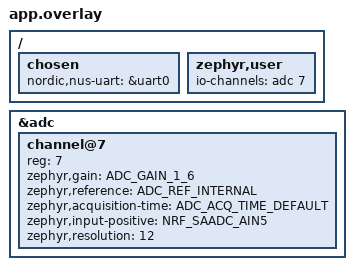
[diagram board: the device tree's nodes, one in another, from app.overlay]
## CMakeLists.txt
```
#
# Copyright (c) 2018 Nordic Semiconductor
#
# SPDX-License-Identifier: LicenseRef-Nordic-5-Clause
#
cmake_minimum_required(VERSION 3.20.0)

find_package(Zephyr REQUIRED HINTS $ENV{ZEPHYR_BASE})
project(homeflow_embedded_final)

# NORDIC SDK APP START
target_sources(app PRIVATE
  src/main.c
  src/bme.c
  src/temp.c
  src/r_enc.c
  src/imu.c
  src/rc_filter.c
  src/hr.c
  src/display.c
  src/ring_buf.c
  src/spi.c
  src/mutexes.c
)

# Include UART ASYNC API adapter
target_sources_ifdef(CONFIG_BT_NUS_UART_ASYNC_ADAPTER app PRIVATE
  src/uart_async_adapter.c
)

# NORDIC SDK APP END

zephyr_library_include_directories(.)
```

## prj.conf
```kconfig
#
# Copyright (c) 2018 Nordic Semiconductor
#
# SPDX-License-Identifier: LicenseRef-Nordic-5-Clause
#

# Enable the UART driver
CONFIG_UART_ASYNC_API=y
CONFIG_NRFX_UARTE0=y
CONFIG_SERIAL=y
CONFIG_POSIX_API=y
CONFIG_NEWLIB_LIBC=y


#enable I2C
CONFIG_I2C=y
CONFIG_I2C_NRFX=y

CONFIG_GPIO=y

# Make sure printk is printing to the UART console
CONFIG_CONSOLE=y
CONFIG_UART_CONSOLE=y

CONFIG_HEAP_MEM_POOL_SIZE=2048

CONFIG_BT=y
CONFIG_BT_PERIPHERAL=y
CONFIG_BT_DEVICE_NAME="HomeFlow"
CONFIG_BT_DEVICE_APPEARANCE=833
CONFIG_BT_MAX_CONN=1
CONFIG_BT_MAX_PAIRED=1

# Enable the NUS service
CONFIG_BT_NUS=y

# Enable bonding
CONFIG_BT_SETTINGS=y
CONFIG_FLASH=y
CONFIG_FLASH_PAGE_LAYOUT=y
CONFIG_FLASH_MAP=y
CONFIG_NVS=y
CONFIG_SETTINGS=y

# Enable DK LED and Buttons library
CONFIG_DK_LIBRARY=y

# This example requires more stack
CONFIG_MAIN_STACK_SIZE=2048
CONFIG_SYSTEM_WORKQUEUE_STACK_SIZE=2048

# Config logger
CONFIG_LOG=y
CONFIG_USE_SEGGER_RTT=y
CONFIG_LOG_BACKEND_RTT=y
CONFIG_LOG_BACKEND_UART=n
CONFIG_LOG_PRINTK=n

CONFIG_ASSERT=y

#enable float printing
CONFIG_STDOUT_CONSOLE=y
CONFIG_NEWLIB_LIBC=y
CONFIG_NEWLIB_LIBC_FLOAT_PRINTF=y

CONFIG_SPI=y
CONFIG_ADC=y
```

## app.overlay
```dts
/*
 * Copyright (c) 2022 Nordic Semiconductor ASA
 *
 * SPDX-License-Identifier: LicenseRef-Nordic-5-Clause
 */

/ {
	chosen {
		nordic,nus-uart = &uart0;
	};

	zephyr,user {
		io-channels = <&adc 7>;
	};
};

&adc {
	#address-cells = <1>;
	#size-cells = <0>;

	channel@7 {
		reg = <7>;
		zephyr,gain = "ADC_GAIN_1_6";
		zephyr,reference = "ADC_REF_INTERNAL";
		zephyr,acquisition-time = <ADC_ACQ_TIME_DEFAULT>;
		zephyr,input-positive = <NRF_SAADC_AIN5>; /* P0.29 */
		zephyr,resolution = <12>;
	};
};
```

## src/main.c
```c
#include <zephyr/types.h>
#include <zephyr/zephyr.h>
#include <stddef.h>
#include <string.h>
#include <errno.h>
#include <zephyr/sys/printk.h>
#include <zephyr/sys/byteorder.h>
#include <zephyr/kernel.h>

#include "bluetooth.c"
#include "../inc/spi.h"
#include "../inc/r_enc.h"
#include "../inc/bme.h"
#include "../inc/temp.h"
#include "../inc/hr.h"
#include "../inc/imu.h"
#include "../inc/display.h"
#include "../inc/mutexes.h"

#include <zephyr/device.h>
#include <zephyr/drivers/i2c.h>
#include <zephyr/devicetree.h>

#include <inttypes.h>
#include <stddef.h>
#include <stdint.h>
#include <stdio.h>

#include <zephyr/device.h>
#include <zephyr/devicetree.h>
#include <zephyr/drivers/adc.h>
#include <zephyr/kernel.h>
#include <zephyr/sys/printk.h>
#include <zephyr/sys/util.h>
#include <hal/nrf_saadc.h>

const struct device* i2c0_dev = DEVICE_DT_GET(DT_NODELABEL(i2c0));
const struct device* gpio1_dev = DEVICE_DT_GET(DT_NODELABEL(gpio1));
const struct device* gpio0_dev = DEVICE_DT_GET(DT_NODELABEL(gpio0));
const struct device* spi1_dev = DEVICE_DT_GET(DT_NODELABEL(spi1));

#define IMU_STACK_SIZE 2048
#define IMU_PRIORITY 8
K_THREAD_STACK_DEFINE(imu_thread_stack, IMU_STACK_SIZE);
struct k_thread imu_thread_data;

#define DISPLAY_STACK_SIZE 1024
#define DISPLAY_PRIORITY 1
K_THREAD_STACK_DEFINE(display_thread_stack, DISPLAY_STACK_SIZE);
struct k_thread display_thread_data;


int main(void)
{
	//ble init
	initialize_ble();

	BME688_Init();

	// IMU init
	init_IMU_cs();
	init_IMU();
	init_RCFilters();

	//r_enc init
	init_enc();

	// Heart rate sensor initialization
	init_hr();

	//mutex init for shared resources
	init_mutexes();
	
	sensor_data data;
	int steps = 0;

	k_thread_create(&imu_thread_data, imu_thread_stack, K_THREAD_STACK_SIZEOF(imu_thread_stack),
					imu_thread_entry, &steps, NULL, NULL, IMU_PRIORITY, 0, K_NO_WAIT);
	k_thread_create(&display_thread_data, display_thread_stack, K_THREAD_STACK_SIZEOF(display_thread_stack),
					display_thread_entry, &data, &steps, NULL, DISPLAY_PRIORITY, 0, K_NO_WAIT);
	k_thread_start(&imu_thread_data);
	k_thread_start(&display_thread_data);

	while (1) {
		k_msleep(1000);

		char temp_buf[10];
		char humidity_buf[10];
		char temp_c_buf[10];
		char gas_buf[10];
		char pressure_buf[10];
		char hr_buf[10];
		char spo2_buf[10];
		char hr_confidence_buf[10];
		char step_buf[10];
		char xl_x_buf[10];
		char xl_y_buf[10];
		char xl_z_buf[10];

		//poll I2C sensors
		k_mutex_lock(&i2c_lock, K_FOREVER);

		//body temp sensor
		data.body_temp = get_body_temp();
		snprintf(temp_buf, sizeof(temp_buf), "BTS:%f", data.body_temp);

		//weather sensor
		BME688_Take_Measurement();
		data.humidity = (float)BME688_Get_Humidity();
		snprintf(humidity_buf, sizeof(humidity_buf), "BMH:%f", data.humidity);
		data.weather_temp = (float)BME688_Get_Temp_C();
		snprintf(temp_c_buf, sizeof(temp_c_buf), "BMT:%f", (data.weather_temp*1.8)+32);
		data.aqi = (float)BME688_Get_Gas();
		snprintf(gas_buf, sizeof(gas_buf), "BMG:%f", data.aqi);
		data.pressure = (float)BME688_Get_Pressure();
		snprintf(pressure_buf, sizeof(pressure_buf), "BMP:%f", data.pressure);

		//hr sensor
		float* hr_data = read_hr();
		data.hr = hr_data[0];
		data.hr_confidence = (int)hr_data[1];
		data.bos = hr_data[2];
		snprintf(hr_buf, sizeof(hr_buf), "BPM:%f", data.hr);
		snprintf(spo2_buf, sizeof(spo2_buf), "BOS:%f", data.bos);
		snprintf(hr_confidence_buf, sizeof(hr_confidence_buf), "HRC:%d", data.hr_confidence);

		k_mutex_unlock(&i2c_lock);

		//read step count
		k_mutex_lock(&steps_lock, K_FOREVER);
		snprintf(step_buf, sizeof(step_buf), "STP:%d", steps);
		k_mutex_unlock(&steps_lock);

		//read IMU readings
		k_mutex_lock(&imu_lock, K_FOREVER);
		snprintf(xl_x_buf, sizeof(xl_x_buf), "XLX:%f", IMU_readings[0]);
		snprintf(xl_y_buf, sizeof(xl_y_buf), "XLY:%f", IMU_readings[1]);
		snprintf(xl_z_buf, sizeof(xl_z_buf), "XLZ:%f", IMU_readings[2]);
		k_mutex_unlock(&imu_lock);

		if (current_conn) {
			bt_nus_send(current_conn, temp_buf, strlen(temp_buf));
			bt_nus_send(current_conn, humidity_buf, strlen(humidity_buf));
			bt_nus_send(current_conn, temp_c_buf, strlen(temp_c_buf));
			bt_nus_send(current_conn, gas_buf, strlen(gas_buf));
			bt_nus_send(current_conn, pressure_buf, strlen(pressure_buf));
			bt_nus_send(current_conn, step_buf, strlen(step_buf));
			bt_nus_send(current_conn, hr_buf, strlen(hr_buf));
			bt_nus_send(current_conn, spo2_buf, strlen(spo2_buf));
			bt_nus_send(current_conn, hr_confidence_buf, strlen(hr_confidence_buf));
			bt_nus_send(current_conn, xl_x_buf, strlen(xl_x_buf));
			bt_nus_send(current_conn, xl_y_buf, strlen(xl_y_buf));
			bt_nus_send(current_conn, xl_z_buf, strlen(xl_z_buf));
		}
	}
	return 0;
}
```

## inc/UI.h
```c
#include "r_enc.h"
#include "display.h"
```

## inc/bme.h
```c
#ifndef BME
#define BME
#include <stdint.h>
#include <zephyr/drivers/i2c.h>

extern const struct device* i2c0_dev;

void BME688_Init();
void BME688_Take_Measurement();
double BME688_Get_Temp_C();
double BME688_Get_Humidity();
double BME688_Get_Pressure();
double BME688_Get_Gas();
#endif
```

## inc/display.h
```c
#ifndef DISPLAY_H
#define DISPLAY_H

#include <zephyr/types.h>
#include <zephyr/drivers/gpio.h>
#include <zephyr/drivers/spi.h>
#include <zephyr/logging/log.h>
#include <stdbool.h>
#include "mutexes.h"

#define P0_03 3
#define P0_04 4

extern int display_var;
extern const struct device* spi1_dev;
extern const struct device* gpio0_dev;
extern volatile bool cw_detected;
extern volatile bool ccw_detected;

typedef struct {
    float hr;
    int hr_confidence;
    float bos;
    float body_temp;
    int steps;
    float weather_temp;
    float humidity;
    float aqi;
    float pressure;
} sensor_data;

typedef enum {
    HEART_RATE_SCREEN,
    BLOOD_OXYGEN_SCREEN,
    BODY_TEMP_SCREEN,
    ACTIVITY_SCREEN,
    WEATHER_SCREEN,
    WARNING_SCREEN,
    NUM_SCREENS // This should always be the last element
} DisplayState;

// Function to initialize the display
void main_display_init(const struct device *spi1_dev, const struct device *gpio0_dev, uint16_t backgroundColor, uint16_t heartColor);

// Function to update the display (could be used for periodic updates or refreshes)
uint16_t main_display_update_test(const struct device *spi1_dev, const struct device *gpio0_dev, uint16_t color);

// Set the row address
void st7789v_set_row_address(const struct device *spi_dev, const struct device *gpio_dev, uint16_t start, uint16_t end);

// Set the column address
void st7789v_set_column_address(const struct device *spi_dev, const struct device *gpio_dev, uint16_t start, uint16_t end);

// Resets and prepares the display hardware
void reset_display(const struct device *reset_gpio);

// Sends commands to the display
void st7789v_send_command(const struct device *spi_dev, const struct device *gpio_dev, uint8_t command);

// Sends data to the display
void st7789v_send_data(const struct device *spi_dev, const struct device *gpio_dev, uint8_t *data, size_t len);

// Initializes the ST7789V display controller
void st7789v_init_display(const struct device *spi_dev, const struct device *gpio_dev);

// Draws a filled rectangle on the display
void st7789v_fill_rect(const struct device *spi_dev, const struct device *gpio_dev, uint16_t x, uint16_t y, uint16_t width, uint16_t height, uint16_t color);

// Optimized function to fill a rectangle with a single color
void st7789v_fill_rect_optimized(const struct device *spi_dev, const struct device *gpio_dev, uint16_t x, uint16_t y, uint16_t width, uint16_t height, uint16_t color);

void draw_thicker_heart(const struct device *spi_dev, const struct device *gpio_dev, int centerX, int centerY, int size, uint16_t color, int thickness);

void display_thread_entry(void *p1, void *p2, void *p3);

#endif // DISPLAY_H
```

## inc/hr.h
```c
#ifndef HR
#define HR
#include <stdint.h>
#include <zephyr/drivers/gpio.h>
#include <zephyr/kernel.h>
#include <zephyr/drivers/i2c.h>

#define MFIO 11 //PIN_0_11
#define RST 12 //PIN_0_12

extern uint8_t HR_ADDR;

extern const struct device* gpio0_dev;
extern const struct device* i2c0_dev;

void init_hr();
float* read_hr();

#endif
```

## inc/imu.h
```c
/*
SPI1 pins:
VIN:  vdd
INT1: P102
SCL: PO31
SDA: PO30
CSAG: P107
SDOAG: P108

SPI3 pins:
VIN:  vdd
INT1 (white): P102
CSAG (brown): P107
SCL/SCK (blue): P115
SDA/MOSI (gray): P113
SDOAG/MISO (orange): P114
*/

#ifndef IMU_H
#define IMU_H

#include <zephyr/kernel.h>
#include <zephyr/drivers/gpio.h>
#include <zephyr/drivers/spi.h>
#include <stdlib.h>
#include <stdio.h>
#include <string.h>
#include <zephyr/sys/printk.h>
#include <zephyr/device.h>
#include <zephyr/logging/log.h>
#include <math.h>
#include <zephyr/sys/ring_buffer.h>
#include <stdbool.h>

#include "rc_filter.h"
#include "ring_buf.h"
#include "mutexes.h"

//relevant registers masks used for IMU
#define CHIPID_REG_READ 0b10001111
#define CTRL_REG1_G_WRITE 0b00010000
#define CTRL_REG1_G_READ 0b10010000
#define ACCEL_X_UPPER 0b10101001
#define ACCEL_X_LOWER 0b10101000
#define ACCEL_Y_UPPER 0b10101011
#define ACCEL_Y_LOWER 0b10101010
#define ACCEL_Z_UPPER 0b10101101
#define ACCEL_Z_LOWER 0b10101100
#define G_X_UPPER 0b10011001
#define G_X_LOWER 0b10011000
#define G_Y_UPPER 0b10011011
#define G_Y_LOWER 0b10011010
#define G_Z_UPPER 0b10011101
#define G_Z_LOWER 0b10011100
#define CTRL_REG1_G_952_ODR 0b11000000
#define INT1_CTRL_READ 0b10001100
#define INT1_CTRL_WRITE 0b00001100
#define INT_IG_XL 0b01000000
#define INT_GEN_CFG_XL_READ 0b10000110
#define INT_GEN_CFG_XL_WRITE 0b00000110
#define XHIE_XL 0b00000010
#define XLIE_XL 0b00000001
#define INT_GEN_THS_X_XL_WRITE 0b00000111
#define INT_GEN_THS_X_XL_READ 0b10000111
#define STATUS_REG_READ 0b10010111
#define INT_GEN_SRC_XL_READ 0b10100110
#define INT_GEN_SRC_XL_WRITE 0b00100110
#define STATUS_REG_READ 0b10010111
#define STATUS_REG_WRITE 0b00010111
#define CTRL_REG6_XL_READ 0b10100000
#define CTRL_REG6_XL_WRITE 0b00100000
#define CTRL_REG6_XL_FS_XL_8G 0b00011000
#define CTRL_REG6_XL_ODR_XL_952 0b11000000
#define FS_XL_4G 0b00010000

#define PIN_1_02 2
#define SPI3_NODE DT_NODELABEL (spi3)
#define MY_GPI01 DT_NODELABEL (gpio1)
#define GPIO_1_CS 7

#define NUM_AXES 6
#define XL_X_IND 0
#define XL_Y_IND 1
#define XL_Z_IND 2
#define G_X_IND 3
#define G_Y_IND 4
#define G_Z_IND 5

#define SAMPLING_INTERVAL_MS 10  // Sampling rate = 1 / SAMPLING_INTERVAL_S
#define ALPHA 0.1

#define A0 0.020083365564211235
#define A1 0.04016673112842247
#define A2 0.020083365564211235
#define B1 -1.5610180758007182
#define B2 0.6413515380575631

// Butterworth filter state
typedef struct {
    float x[2];  // Input samples
    float y[2];  // Output samples
} ButterworthFilter;

extern const struct device *spi3_dev;
extern struct spi_config spi3_cfg;
extern const struct device* gpio0_dev;
extern const struct device *gpio1_dev;
// extern struct gpio_callback gpio_cb;

//order of indices: xl_x, xl_y, xl_z, g_x, g_y, g_z
extern RCFilter lp_filters[NUM_AXES]; 
extern float cutoff_freqs[NUM_AXES];

extern volatile float IMU_readings[NUM_AXES]; //sensor readings in g's and dps
extern volatile int interrupt_called;
extern volatile int max_x;
extern volatile float filtered_imu_data[3];
extern volatile float threshold;

void spi_read_reg(uint8_t reg, uint8_t values[], uint8_t size);
void spi_write_reg(uint8_t reg, uint8_t data, uint8_t size);
void init_IMU();
void init_IMU_interrupts();
void IMU_interrupt_cb(const struct device *dev, struct gpio_callback *cb, uint32_t pins);
void init_IMU_cs();
float poll_IMU(); //returns magnitude of IMU readings
void init_RCFilters();
void imu_thread_entry(void *p1, void *p2, void *p3);
float calc_magnitude(float x, float y, float z);
float ema_filter(float new_mag, float old_mag);
void init_butterworth_filter(ButterworthFilter* filter);
float butterworth_filter(ButterworthFilter* filter, float input);
bool detect_step(float magnitude, ring_buf* samps, ring_buf* intervals, long* last_step_time_ms);

#endif
```

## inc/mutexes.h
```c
#pragma once

#include <zephyr/kernel.h>

extern void init_mutexes();

extern struct k_mutex steps_lock; //for steps
extern struct k_mutex i2c_lock; //for sensor_data struct in main
extern struct k_mutex imu_lock; //for IMU_readings[]
```

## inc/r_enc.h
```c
#ifndef R_ENC_H
#define R_ENC_H

#include <zephyr/kernel.h>
#include <zephyr/drivers/gpio.h>
#include <stdlib.h>
#include <stdio.h>
#include <string.h>
#include <zephyr/sys/printk.h>
#include <zephyr/logging/log.h>
#include <stdbool.h>

// Assign pins A, B, and BTN to P104, P105, & P106 respectively
#define P0_03 3
#define P0_04 4
#define P1_08 8 // NOTE: P0_05 didn't work for some reason (the intended pin), might be due to HW issues on DK board
#define PIN_A 24
#define PIN_B 25
#define PIN_C 0
#define PIN_LED 13

extern const struct device *gpio0_dev;
extern const struct device *gpio1_dev;
extern volatile bool cw_detected;
extern volatile bool ccw_detected;

//initialize gpios for encoder
void init_enc();
void set_decoder_state(const struct device *dev, uint8_t state);
void process_encoder_input(const struct device *dev, uint8_t pin_a_val, uint8_t pin_b_val);
void encoder_isr(const struct device *dev, struct gpio_callback *cb, uint32_t pins);
void click_isr(const struct device *dev, struct gpio_callback *cb, uint32_t pins);
void debounce_twist(const struct device *dev, uint8_t enc_val);
void debounce_button(const struct device *dev);
void check_enc_btn();

#endif
```

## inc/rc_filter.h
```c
#ifndef RC_FILTER_H
#define RC_FILTER_H

//SW RC circuit filter
typedef struct {
	float coeff[2];
	float out[2];

} RCFilter;

void RCFilter_Init(RCFilter *filt, float cutoffFreqHz, float sampleTimeS);
float RCFilter_Update(RCFilter *filt, float inp);

#endif
```

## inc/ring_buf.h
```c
#define BUF_SIZE 10

typedef struct {
    float buffer[BUF_SIZE];
    int curr_index;
} ring_buf;

void insert_val(float accel, ring_buf* b);
float get_rolling_avg(ring_buf* b);
```

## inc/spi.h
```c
#ifndef SPI_H
#define SPI_H

#include <zephyr/types.h>
#include <zephyr/drivers/spi.h>

extern struct spi_config spi_cfg; // Declare the external SPI configuration to be used by other files.

int spi_write1(const struct device *spi_dev, uint8_t *data, size_t data_len, struct spi_config sg);

#endif // SPI_H
```

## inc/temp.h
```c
#include <stdint.h>
#include <zephyr/drivers/i2c.h>
extern const struct device* i2c0_dev;

float get_body_temp();
```

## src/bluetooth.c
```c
/*
 * Copyright (c) 2018 Nordic Semiconductor ASA
 *
 * SPDX-License-Identifier: LicenseRef-Nordic-5-Clause
 */

/** @file
 *  @brief Nordic UART Bridge Service (NUS) sample
 */
#include "../inc/uart_async_adapter.h"

#include <zephyr/types.h>
#include <zephyr/kernel.h>
#include <zephyr/drivers/uart.h>
#include <zephyr/usb/usb_device.h>

#include <zephyr/device.h>
#include <zephyr/devicetree.h>
#include <soc.h>

#include <zephyr/bluetooth/bluetooth.h>
#include <zephyr/bluetooth/uuid.h>
#include <zephyr/bluetooth/gatt.h>
#include <zephyr/bluetooth/hci.h>

#include <bluetooth/services/nus.h>

#include <dk_buttons_and_leds.h>

#include <zephyr/settings/settings.h>

#include <stdio.h>

#include <zephyr/logging/log.h>

#include "../inc/bluetooth.h"

#define LOG_MODULE_NAME peripheral_uart
LOG_MODULE_REGISTER(LOG_MODULE_NAME);

#define STACKSIZE 1024
#define PRIORITY 7

#define DEVICE_NAME CONFIG_BT_DEVICE_NAME
#define DEVICE_NAME_LEN	(sizeof(DEVICE_NAME) - 1)

#define RUN_STATUS_LED DK_LED1
#define RUN_LED_BLINK_INTERVAL 1000

#define CON_STATUS_LED DK_LED2

#define KEY_PASSKEY_ACCEPT DK_BTN1_MSK
#define KEY_PASSKEY_REJECT DK_BTN2_MSK

#define UART_BUF_SIZE CONFIG_BT_NUS_UART_BUFFER_SIZE
#define UART_WAIT_FOR_BUF_DELAY K_MSEC(50)
#define UART_WAIT_FOR_RX CONFIG_BT_NUS_UART_RX_WAIT_TIME

K_SEM_DEFINE(ble_init_ok, 0, 1);

static struct bt_conn *current_conn;
static struct bt_conn *auth_conn;

static const struct device *uart = DEVICE_DT_GET(DT_CHOSEN(nordic_nus_uart));
static struct k_work_delayable uart_work;

struct uart_data_t {
	void *fifo_reserved;
	uint8_t data[UART_BUF_SIZE];
	uint16_t len;
};

static K_FIFO_DEFINE(fifo_uart_tx_data);
static K_FIFO_DEFINE(fifo_uart_rx_data);

const struct bt_data ad[] = {
	BT_DATA_BYTES(BT_DATA_FLAGS, (BT_LE_AD_GENERAL | BT_LE_AD_NO_BREDR)),
	BT_DATA(BT_DATA_NAME_COMPLETE, DEVICE_NAME, DEVICE_NAME_LEN),
};

const struct bt_data sd[] = {
	BT_DATA_BYTES(BT_DATA_UUID128_ALL, BT_UUID_NUS_VAL),
};

#if CONFIG_BT_NUS_UART_ASYNC_ADAPTER
UART_ASYNC_ADAPTER_INST_DEFINE(async_adapter);
#else
static const struct device *const async_adapter;
#endif

static void uart_cb(const struct device *dev, struct uart_event *evt, void *user_data)
{
	ARG_UNUSED(dev);

	static size_t aborted_len;
	struct uart_data_t *buf;
	static uint8_t *aborted_buf;
	static bool disable_req;

	switch (evt->type) {
	case UART_TX_DONE:
		LOG_DBG("UART_TX_DONE");
		if ((evt->data.tx.len == 0) ||
		    (!evt->data.tx.buf)) {
			return;
		}

		if (aborted_buf) {
			buf = CONTAINER_OF(aborted_buf, struct uart_data_t,
					   data);
			aborted_buf = NULL;
			aborted_len = 0;
		} else {
			buf = CONTAINER_OF(evt->data.tx.buf, struct uart_data_t,
					   data);
		}

		k_free(buf);

		buf = k_fifo_get(&fifo_uart_tx_data, K_NO_WAIT);
		if (!buf) {
			return;
		}

		if (uart_tx(uart, buf->data, buf->len, SYS_FOREVER_MS)) {
			LOG_WRN("Failed to send data over UART");
		}

		break;

	case UART_RX_RDY:
		LOG_DBG("UART_RX_RDY");
		buf = CONTAINER_OF(evt->data.rx.buf, struct uart_data_t, data);
		buf->len += evt->data.rx.len;

		if (disable_req) {
			return;
		}

		if ((evt->data.rx.buf[buf->len - 1] == '\n') ||
		    (evt->data.rx.buf[buf->len - 1] == '\r')) {
			disable_req = true;
			uart_rx_disable(uart);
		}

		break;

	case UART_RX_DISABLED:
		LOG_DBG("UART_RX_DISABLED");
		disable_req = false;

		buf = k_malloc(sizeof(*buf));
		if (buf) {
			buf->len = 0;
		} else {
			LOG_WRN("Not able to allocate UART receive buffer");
			k_work_reschedule(&uart_work, UART_WAIT_FOR_BUF_DELAY);
			return;
		}

		uart_rx_enable(uart, buf->data, sizeof(buf->data),
			       UART_WAIT_FOR_RX);

		break;

	case UART_RX_BUF_REQUEST:
		LOG_DBG("UART_RX_BUF_REQUEST");
		buf = k_malloc(sizeof(*buf));
		if (buf) {
			buf->len = 0;
			uart_rx_buf_rsp(uart, buf->data, sizeof(buf->data));
		} else {
			LOG_WRN("Not able to allocate UART receive buffer");
		}

		break;

	case UART_RX_BUF_RELEASED:
		LOG_DBG("UART_RX_BUF_RELEASED");
		buf = CONTAINER_OF(evt->data.rx_buf.buf, struct uart_data_t,
				   data);

		if (buf->len > 0) {
			k_fifo_put(&fifo_uart_rx_data, buf);
		} else {
			k_free(buf);
		}

		break;

	case UART_TX_ABORTED:
		LOG_DBG("UART_TX_ABORTED");
		if (!aborted_buf) {
			aborted_buf = (uint8_t *)evt->data.tx.buf;
		}

		aborted_len += evt->data.tx.len;
		buf = CONTAINER_OF(aborted_buf, struct uart_data_t,
				   data);

		uart_tx(uart, &buf->data[aborted_len],
			buf->len - aborted_len, SYS_FOREVER_MS);

		break;

	default:
		break;
	}
}

static void uart_work_handler(struct k_work *item)
{
	struct uart_data_t *buf;

	buf = k_malloc(sizeof(*buf));
	if (buf) {
		buf->len = 0;
	} else {
		LOG_WRN("Not able to allocate UART receive buffer");
		k_work_reschedule(&uart_work, UART_WAIT_FOR_BUF_DELAY);
		return;
	}

	uart_rx_enable(uart, buf->data, sizeof(buf->data), UART_WAIT_FOR_RX);
}

static bool uart_test_async_api(const struct device *dev)
{
	const struct uart_driver_api *api =
			(const struct uart_driver_api *)dev->api;

	return (api->callback_set != NULL);
}

static int uart_init(void)
{
	int err;
	int pos;
	struct uart_data_t *rx;
	struct uart_data_t *tx;

	if (!device_is_ready(uart)) {
		return -ENODEV;
	}

	if (IS_ENABLED(CONFIG_USB_DEVICE_STACK)) {
		err = usb_enable(NULL);
		if (err && (err != -EALREADY)) {
			LOG_ERR("Failed to enable USB");
			return err;
		}
	}

	rx = k_malloc(sizeof(*rx));
	if (rx) {
		rx->len = 0;
	} else {
		return -ENOMEM;
	}

	k_work_init_delayable(&uart_work, uart_work_handler);


	if (IS_ENABLED(CONFIG_BT_NUS_UART_ASYNC_ADAPTER) && !uart_test_async_api(uart)) {
		/* Implement API adapter */
		uart_async_adapter_init(async_adapter, uart);
		uart = async_adapter;
	}

	err = uart_callback_set(uart, uart_cb, NULL);
	if (err) {
		k_free(rx);
		LOG_ERR("Cannot initialize UART callback");
		return err;
	}

	if (IS_ENABLED(CONFIG_UART_LINE_CTRL)) {
		LOG_INF("Wait for DTR");
		while (true) {
			uint32_t dtr = 0;

			uart_line_ctrl_get(uart, UART_LINE_CTRL_DTR, &dtr);
			if (dtr) {
				break;
			}
			/* Give CPU resources to low priority threads. */
			k_sleep(K_MSEC(100));
		}
		LOG_INF("DTR set");
		err = uart_line_ctrl_set(uart, UART_LINE_CTRL_DCD, 1);
		if (err) {
			LOG_WRN("Failed to set DCD, ret code %d", err);
		}
		err = uart_line_ctrl_set(uart, UART_LINE_CTRL_DSR, 1);
		if (err) {
			LOG_WRN("Failed to set DSR, ret code %d", err);
		}
	}

	tx = k_malloc(sizeof(*tx));

	if (tx) {
		pos = snprintf(tx->data, sizeof(tx->data),
			       "Starting Nordic UART service example\r\n");

		if ((pos < 0) || (pos >= sizeof(tx->data))) {
			k_free(rx);
			k_free(tx);
			LOG_ERR("snprintf returned %d", pos);
			return -ENOMEM;
		}

		tx->len = pos;
	} else {
		k_free(rx);
		return -ENOMEM;
	}

	err = uart_tx(uart, tx->data, tx->len, SYS_FOREVER_MS);
	if (err) {
		k_free(rx);
		k_free(tx);
		LOG_ERR("Cannot display welcome message (err: %d)", err);
		return err;
	}

	err = uart_rx_enable(uart, rx->data, sizeof(rx->data), 50);
	if (err) {
		LOG_ERR("Cannot enable uart reception (err: %d)", err);
		/* Free the rx buffer only because the tx buffer will be handled in the callback */
		k_free(rx);
	}

	return err;
}

static void connected(struct bt_conn *conn, uint8_t err)
{
	char addr[BT_ADDR_LE_STR_LEN];

	if (err) {
		LOG_ERR("Connection failed (err %u)", err);
		return;
	}

	bt_addr_le_to_str(bt_conn_get_dst(conn), addr, sizeof(addr));
	LOG_INF("Connected %s", addr);

	current_conn = bt_conn_ref(conn);

	dk_set_led_on(CON_STATUS_LED);
}

static void disconnected(struct bt_conn *conn, uint8_t reason)
{
	char addr[BT_ADDR_LE_STR_LEN];

	bt_addr_le_to_str(bt_conn_get_dst(conn), addr, sizeof(addr));

	LOG_INF("Disconnected: %s (reason %u)", addr, reason);

	if (auth_conn) {
		bt_conn_unref(auth_conn);
		auth_conn = NULL;
	}

	if (current_conn) {
		bt_conn_unref(current_conn);
		current_conn = NULL;
		dk_set_led_off(CON_STATUS_LED);
	}
}

#ifdef CONFIG_BT_NUS_SECURITY_ENABLED
static void security_changed(struct bt_conn *conn, bt_security_t level,
			     enum bt_security_err err)
{
	char addr[BT_ADDR_LE_STR_LEN];

	bt_addr_le_to_str(bt_conn_get_dst(conn), addr, sizeof(addr));

	if (!err) {
		LOG_INF("Security changed: %s level %u", addr, level);
	} else {
		LOG_WRN("Security failed: %s level %u err %d", addr,
			level, err);
	}
}
#endif

BT_CONN_CB_DEFINE(conn_callbacks) = {
	.connected    = connected,
	.disconnected = disconnected,
#ifdef CONFIG_BT_NUS_SECURITY_ENABLED
	.security_changed = security_changed,
#endif
};

#if defined(CONFIG_BT_NUS_SECURITY_ENABLED)
static void auth_passkey_display(struct bt_conn *conn, unsigned int passkey)
{
	char addr[BT_ADDR_LE_STR_LEN];

	bt_addr_le_to_str(bt_conn_get_dst(conn), addr, sizeof(addr));

	LOG_INF("Passkey for %s: %06u", addr, passkey);
}

static void auth_passkey_confirm(struct bt_conn *conn, unsigned int passkey)
{
	char addr[BT_ADDR_LE_STR_LEN];

	auth_conn = bt_conn_ref(conn);

	bt_addr_le_to_str(bt_conn_get_dst(conn), addr, sizeof(addr));

	LOG_INF("Passkey for %s: %06u", addr, passkey);
	LOG_INF("Press Button 1 to confirm, Button 2 to reject.");
}


static void auth_cancel(struct bt_conn *conn)
{
	char addr[BT_ADDR_LE_STR_LEN];

	bt_addr_le_to_str(bt_conn_get_dst(conn), addr, sizeof(addr));

	LOG_INF("Pairing cancelled: %s", addr);
}


static void pairing_complete(struct bt_conn *conn, bool bonded)
{
	char addr[BT_ADDR_LE_STR_LEN];

	bt_addr_le_to_str(bt_conn_get_dst(conn), addr, sizeof(addr));

	LOG_INF("Pairing completed: %s, bonded: %d", addr, bonded);
}


static void pairing_failed(struct bt_conn *conn, enum bt_security_err reason)
{
	char addr[BT_ADDR_LE_STR_LEN];

	bt_addr_le_to_str(bt_conn_get_dst(conn), addr, sizeof(addr));

	LOG_INF("Pairing failed conn: %s, reason %d", addr, reason);
}


struct bt_conn_auth_cb conn_auth_callbacks = {
	.passkey_display = auth_passkey_display,
	.passkey_confirm = auth_passkey_confirm,
	.cancel = auth_cancel,
};

static struct bt_conn_auth_info_cb conn_auth_info_callbacks = {
	.pairing_complete = pairing_complete,
	.pairing_failed = pairing_failed
};
#else
struct bt_conn_auth_cb conn_auth_callbacks;
static struct bt_conn_auth_info_cb conn_auth_info_callbacks;
#endif

static void bt_receive_cb(struct bt_conn *conn, const uint8_t *const data,
			  uint16_t len)
{
	int err;
	char addr[BT_ADDR_LE_STR_LEN] = {0};

	bt_addr_le_to_str(bt_conn_get_dst(conn), addr, ARRAY_SIZE(addr));

	LOG_INF("Received data from: %s", addr);

	for (uint16_t pos = 0; pos != len;) {
		struct uart_data_t *tx = k_malloc(sizeof(*tx));

		if (!tx) {
			LOG_WRN("Not able to allocate UART send data buffer");
			return;
		}

		/* Keep the last byte of TX buffer for potential LF char. */
		size_t tx_data_size = sizeof(tx->data) - 1;

		if ((len - pos) > tx_data_size) {
			tx->len = tx_data_size;
		} else {
			tx->len = (len - pos);
		}

		memcpy(tx->data, &data[pos], tx->len);

		pos += tx->len;

		/* Append the LF character when the CR character triggered
		 * transmission from the peer.
		 */
		if ((pos == len) && (data[len - 1] == '\r')) {
			tx->data[tx->len] = '\n';
			tx->len++;
		}

		err = uart_tx(uart, tx->data, tx->len, SYS_FOREVER_MS);
		if (err) {
			k_fifo_put(&fifo_uart_tx_data, tx);
		}
	}
}

static struct bt_nus_cb nus_cb = {
	.received = bt_receive_cb,
};

// void error(void)
// {
// 	dk_set_leds_state(DK_ALL_LEDS_MSK, DK_NO_LEDS_MSK);

// 	while (true) {
// 		/* Spin for ever */
// 		k_sleep(K_MSEC(1000));
// 	}
// }

#ifdef CONFIG_BT_NUS_SECURITY_ENABLED
static void num_comp_reply(bool accept)
{
	if (accept) {
		bt_conn_auth_passkey_confirm(auth_conn);
		LOG_INF("Numeric Match, conn %p", (void *)auth_conn);
	} else {
		bt_conn_auth_cancel(auth_conn);
		LOG_INF("Numeric Reject, conn %p", (void *)auth_conn);
	}

	bt_conn_unref(auth_conn);
	auth_conn = NULL;
}

void button_changed(uint32_t button_state, uint32_t has_changed)
{
	uint32_t buttons = button_state & has_changed;

	if (auth_conn) {
		if (buttons & KEY_PASSKEY_ACCEPT) {
			num_comp_reply(true);
		}

		if (buttons & KEY_PASSKEY_REJECT) {
			num_comp_reply(false);
		}
	}
}
#endif /* CONFIG_BT_NUS_SECURITY_ENABLED */

static void configure_gpio(void)
{
	int err;

#ifdef CONFIG_BT_NUS_SECURITY_ENABLED
	err = dk_buttons_init(button_changed);
	if (err) {
		LOG_ERR("Cannot init buttons (err: %d)", err);
	}
#endif /* CONFIG_BT_NUS_SECURITY_ENABLED */

	err = dk_leds_init();
	if (err) {
		LOG_ERR("Cannot init LEDs (err: %d)", err);
	}
}

void ble_write_thread(void)
{
	/* Don't go any further until BLE is initialized */
	k_sem_take(&ble_init_ok, K_FOREVER);

	for (;;) {
		/* Wait indefinitely for data to be sent over bluetooth */
		struct uart_data_t *buf = k_fifo_get(&fifo_uart_rx_data,
						     K_FOREVER);

		if (bt_nus_send(NULL, buf->data, buf->len)) {
			LOG_WRN("Failed to send data over BLE connection");
		}

		k_free(buf);
	}
}

K_THREAD_DEFINE(ble_write_thread_id, STACKSIZE, ble_write_thread, NULL, NULL,
		NULL, PRIORITY, 0, 0);

void initialize_ble() {
	configure_gpio();

	int err = uart_init();
	if (err) {
		// error();
	}

	if (IS_ENABLED(CONFIG_BT_NUS_SECURITY_ENABLED)) {
		err = bt_conn_auth_cb_register(&conn_auth_callbacks);
		if (err) {
			printk("Failed to register authorization callbacks.\n");
			return 0;
		}

		err = bt_conn_auth_info_cb_register(&conn_auth_info_callbacks);
		if (err) {
			printk("Failed to register authorization info callbacks.\n");
			return 0;
		}
	}

	err = bt_enable(NULL);
	if (err) {
		// error();
	}

	LOG_INF("Bluetooth initialized");

	k_sem_give(&ble_init_ok);

	if (IS_ENABLED(CONFIG_SETTINGS)) {
		settings_load();
	}

	err = bt_nus_init(&nus_cb);
	if (err) {
		LOG_ERR("Failed to initialize UART service (err: %d)", err);
		return 0;
	}

	err = bt_le_adv_start(BT_LE_ADV_CONN, ad, ARRAY_SIZE(ad), sd,
			      ARRAY_SIZE(sd));
	if (err) {
		LOG_ERR("Advertising failed to start (err %d)", err);
		return 0;
	}

}
```
